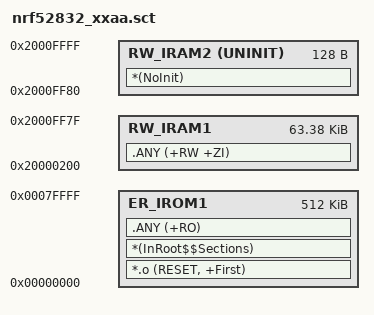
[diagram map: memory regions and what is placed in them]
; *************************************************************
; *** Scatter-Loading Description File generated by uVision ***
; *************************************************************

LR_IROM1 0x00000000 0x00080000  {    ; load region size_region
  ER_IROM1 0x00000000 0x00080000  {  ; load address = execution address
   *.o (RESET, +First)
   *(InRoot$$Sections)
   .ANY (+RO)
  }
  RW_IRAM1 0x20000200 0x0000FD80  {  ; RW data
   .ANY (+RW +ZI)
  }
  RW_IRAM2 0x2000FF80 UNINIT 0x00000080  {
   *(NoInit)
  }
}

